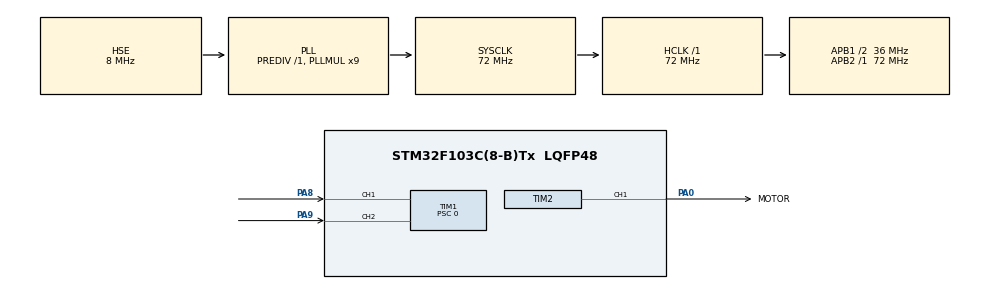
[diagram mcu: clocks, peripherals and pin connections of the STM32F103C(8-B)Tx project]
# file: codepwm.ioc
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Mcu.Family=STM32F1
Mcu.Name=STM32F103C(8-B)Tx
Mcu.Package=LQFP48
NVIC.PriorityGroup=NVIC_PRIORITYGROUP_4
NVIC.TIM3_IRQn=true\:0\:0\:false\:false\:true\:true\:true
PA0-WKUP.GPIO_Label=MOTOR
PA0-WKUP.Signal=S_TIM2_CH1_ETR
PA13.Mode=Serial_Wire
PA13.Signal=SYS_JTMS-SWDIO
PA14.Mode=Serial_Wire
PA14.Signal=SYS_JTCK-SWCLK
PA8.Signal=S_TIM1_CH1
PA9.Signal=S_TIM1_CH2
PD0-OSC_IN.Mode=HSE-External-Oscillator
PD0-OSC_IN.Signal=RCC_OSC_IN
PD1-OSC_OUT.Mode=HSE-External-Oscillator
PD1-OSC_OUT.Signal=RCC_OSC_OUT
ProjectManager.HeapSize=0x200
ProjectManager.StackSize=0x400
ProjectManager.TargetToolchain=MDK-ARM V5.32
RCC.AHBFreq_Value=72000000
RCC.APB1CLKDivider=RCC_HCLK_DIV2
RCC.APB1Freq_Value=36000000
RCC.APB1TimFreq_Value=72000000
RCC.APB2Freq_Value=72000000
RCC.APB2TimFreq_Value=72000000
RCC.HCLKFreq_Value=72000000
RCC.PLLMUL=RCC_PLL_MUL9
RCC.PLLSourceVirtual=RCC_PLLSOURCE_HSE
RCC.SYSCLKFreq_VALUE=72000000
RCC.SYSCLKSource=RCC_SYSCLKSOURCE_PLLCLK
RCC.USBFreq_Value=72000000
SH.S_TIM1_CH1.0=TIM1_CH1,Encoder_Interface
SH.S_TIM1_CH2.0=TIM1_CH2,Encoder_Interface
SH.S_TIM2_CH1_ETR.0=TIM2_CH1,PWM Generation1 CH1
TIM1.EncoderMode=TIM_ENCODERMODE_TI12
TIM1.Period=1560-1
TIM1.Prescaler=0
TIM2.Channel-PWM\ Generation1\ CH1=TIM_CHANNEL_1
TIM2.Period=100-1
TIM2.Prescaler=71
TIM3.Period=65535
TIM3.Prescaler=72-1
VP_TIM3_VS_ClockSourceINT.Mode=Internal
board=custom

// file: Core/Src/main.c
/* USER CODE BEGIN Header */
/**
  ******************************************************************************
  * @file           : main.c
  * @brief          : Main program body
  ******************************************************************************
  * @attention
  *
  * <h2><center>&copy; Copyright (c) 2026 STMicroelectronics.
  * All rights reserved.</center></h2>
  *
  * This software component is licensed by ST under BSD 3-Clause license,
  * the "License"; You may not use this file except in compliance with the
  * License. You may obtain a copy of the License at:
  *                        opensource.org/licenses/BSD-3-Clause
  *
  ******************************************************************************
  */
/* USER CODE END Header */
#include "main.h"

/* USER CODE BEGIN Includes */
#include <stdint.h>
/* USER CODE END Includes */

/* USER CODE BEGIN PTD */
typedef struct
{
    float Kp;
    float Ki;
    float Kd;

    float Integral;
    float Last_Error;
} PID_TypeDef;
/**
 * @brief 位置�? PID 计算函数
 * @param pid: 结构体指�?
 * @param target: 目标�? (比如目标温度 40�?)
 * @param measure: 当前测量�? (比如当前温度 30�?)
 * @return: 计算出的控制�? (比如 PWM 占空�?)
 */

/* USER CODE END PTD */

TIM_HandleTypeDef htim1;
TIM_HandleTypeDef htim2;
TIM_HandleTypeDef htim3;

/* USER CODE BEGIN PV */

volatile float rpm = 0.0f;
volatile float target_rpm = 100.0f;

PID_TypeDef speed_pid;
/* USER CODE END PV */

void SystemClock_Config(void);
static void MX_GPIO_Init(void);
static void MX_TIM2_Init(void);
static void MX_TIM1_Init(void);
static void MX_TIM3_Init(void);

/* USER CODE BEGIN 0 */
#define PID_DT                0.05f
#define PWM_MAX               100.0f
#define PWM_START_MIN          30.0f
#define RPM_STARTED_THRESHOLD   5.0f
#define ENCODER_CPR          1560.0f

float PID_Calculate(PID_TypeDef *pid,
                    float target,
                    float actual)
{
    float error;
    float derivative;
    float integral_candidate;
    float output;

    /* 1. 计算当前误差 */
    error = target - actual;

    /* 2. 微分：计算误差变化�?�度 */
    derivative = (error - pid->Last_Error) / PID_DT;

    /*
     * 3. 仅在未饱和或积分能使输出�?出饱和时更新积分�?
     * 避免高目标转速时积分持续堆积，随后出现冲高和断续停转�?
     */
    integral_candidate = pid->Integral + pid->Ki * error * PID_DT;
    output = pid->Kp * error
           + integral_candidate
           + pid->Kd * derivative;

    if (((output >= 0.0f) && (output <= PWM_MAX))
        || ((output > PWM_MAX) && (error < 0.0f))
        || ((output < 0.0f) && (error > 0.0f)))
    {
        pid->Integral = integral_candidate;
    }

    if (pid->Integral > PWM_MAX)
    {
        pid->Integral = PWM_MAX;
    }
    else if (pid->Integral < 0.0f)
    {
        pid->Integral = 0.0f;
    }

    /* 4. 使用�?终积分�?�计�? PID 输出 */
    output = pid->Kp * error
           + pid->Integral
           + pid->Kd * derivative;

    /* 保存本次误差，下�?次计算微分时使用 */
    pid->Last_Error = error;

    /* 5. PWM 限幅 */
    if (output > PWM_MAX)
    {
        output = PWM_MAX;
    }

    if (output < 0.0f)
    {
        output = 0.0f;
    }

    return output;
}
/* USER CODE END 0 */

int main(void)
{

  /* MCU Configuration--------------------------------------------------------*/

  /* Reset of all peripherals, Initializes the Flash interface and the Systick. */
  HAL_Init();

  /* Configure the system clock */
  SystemClock_Config();

  /* Initialize all configured peripherals */
  MX_GPIO_Init();
  MX_TIM2_Init();
  MX_TIM1_Init();
  MX_TIM3_Init();
  /* USER CODE BEGIN 2 */

HAL_TIM_PWM_Start(&htim2, TIM_CHANNEL_1);
__HAL_TIM_SET_COMPARE(&htim2, TIM_CHANNEL_1, 0);
/* PID 初始参数 */
speed_pid.Kp = 0.5f;
speed_pid.Ki = 0.20f;
speed_pid.Kd = 0.00f;

speed_pid.Integral = 0.0f;
speed_pid.Last_Error = 0.0f;

/* 启动编码�? */
HAL_TIM_Encoder_Start(&htim1, TIM_CHANNEL_ALL);
__HAL_TIM_SET_COUNTER(&htim1, 0);

/* �?有控制变量初始化后，再启�? 50 ms 控制周期 */
HAL_TIM_Base_Start_IT(&htim3);
  /* USER CODE END 2 */

  /* Infinite loop */
  /* USER CODE BEGIN WHILE */
  while (1)
  {

//	  if (count >60000)
//    {
//      count = 0;
//      __HAL_TIM_SET_COUNTER(&htim1, 0);
//    }
//    else if (count > 20)
//    {
//      count = 20;
//      __HAL_TIM_SET_COUNTER(&htim1, 20);
//    }
//
//__HAL_TIM_SET_COMPARE(&htim2, TIM_CHANNEL_1, count*5);

//
//  HAL_Delay(3000);

//  __HAL_TIM_SET_COMPARE(&htim2, TIM_CHANNEL_1, 0);
//  HAL_Delay(2000);

//  __HAL_TIM_SET_COMPARE(&htim2, TIM_CHANNEL_1, 50);
//  HAL_Delay(3000);
    /* USER CODE END WHILE */

  }
}

void SystemClock_Config(void)
{
  RCC_OscInitTypeDef RCC_OscInitStruct = {0};
  RCC_ClkInitTypeDef RCC_ClkInitStruct = {0};

  /** Initializes the RCC Oscillators according to the specified parameters
  * in the RCC_OscInitTypeDef structure.
  */
  RCC_OscInitStruct.OscillatorType = RCC_OSCILLATORTYPE_HSE;
  RCC_OscInitStruct.HSEState = RCC_HSE_ON;
  RCC_OscInitStruct.HSEPredivValue = RCC_HSE_PREDIV_DIV1;
  RCC_OscInitStruct.HSIState = RCC_HSI_ON;
  RCC_OscInitStruct.PLL.PLLState = RCC_PLL_ON;
  RCC_OscInitStruct.PLL.PLLSource = RCC_PLLSOURCE_HSE;
  RCC_OscInitStruct.PLL.PLLMUL = RCC_PLL_MUL9;
  if (HAL_RCC_OscConfig(&RCC_OscInitStruct) != HAL_OK)
  {
    Error_Handler();
  }
  /** Initializes the CPU, AHB and APB buses clocks
  */
  RCC_ClkInitStruct.ClockType = RCC_CLOCKTYPE_HCLK|RCC_CLOCKTYPE_SYSCLK
                              |RCC_CLOCKTYPE_PCLK1|RCC_CLOCKTYPE_PCLK2;
  RCC_ClkInitStruct.SYSCLKSource = RCC_SYSCLKSOURCE_PLLCLK;
  RCC_ClkInitStruct.AHBCLKDivider = RCC_SYSCLK_DIV1;
  RCC_ClkInitStruct.APB1CLKDivider = RCC_HCLK_DIV2;
  RCC_ClkInitStruct.APB2CLKDivider = RCC_HCLK_DIV1;

  if (HAL_RCC_ClockConfig(&RCC_ClkInitStruct, FLASH_LATENCY_2) != HAL_OK)
  {
    Error_Handler();
  }
}

static void MX_TIM1_Init(void)
{

  TIM_Encoder_InitTypeDef sConfig = {0};
  TIM_MasterConfigTypeDef sMasterConfig = {0};

  htim1.Instance = TIM1;
  htim1.Init.Prescaler = 0;
  htim1.Init.CounterMode = TIM_COUNTERMODE_UP;
  htim1.Init.Period = 1560-1;
  htim1.Init.ClockDivision = TIM_CLOCKDIVISION_DIV1;
  htim1.Init.RepetitionCounter = 0;
  htim1.Init.AutoReloadPreload = TIM_AUTORELOAD_PRELOAD_DISABLE;
  sConfig.EncoderMode = TIM_ENCODERMODE_TI12;
  sConfig.IC1Polarity = TIM_ICPOLARITY_RISING;
  sConfig.IC1Selection = TIM_ICSELECTION_DIRECTTI;
  sConfig.IC1Prescaler = TIM_ICPSC_DIV1;
  sConfig.IC1Filter = 0;
  sConfig.IC2Polarity = TIM_ICPOLARITY_RISING;
  sConfig.IC2Selection = TIM_ICSELECTION_DIRECTTI;
  sConfig.IC2Prescaler = TIM_ICPSC_DIV1;
  sConfig.IC2Filter = 0;
  if (HAL_TIM_Encoder_Init(&htim1, &sConfig) != HAL_OK)
  {
    Error_Handler();
  }
  sMasterConfig.MasterOutputTrigger = TIM_TRGO_RESET;
  sMasterConfig.MasterSlaveMode = TIM_MASTERSLAVEMODE_DISABLE;
  if (HAL_TIMEx_MasterConfigSynchronization(&htim1, &sMasterConfig) != HAL_OK)
  {
    Error_Handler();
  }

}

static void MX_TIM2_Init(void)
{

  TIM_MasterConfigTypeDef sMasterConfig = {0};
  TIM_OC_InitTypeDef sConfigOC = {0};

  htim2.Instance = TIM2;
  htim2.Init.Prescaler = 71;
  htim2.Init.CounterMode = TIM_COUNTERMODE_UP;
  htim2.Init.Period = 100-1;
  htim2.Init.ClockDivision = TIM_CLOCKDIVISION_DIV1;
  htim2.Init.AutoReloadPreload = TIM_AUTORELOAD_PRELOAD_DISABLE;
  if (HAL_TIM_PWM_Init(&htim2) != HAL_OK)
  {
    Error_Handler();
  }
  sMasterConfig.MasterOutputTrigger = TIM_TRGO_RESET;
  sMasterConfig.MasterSlaveMode = TIM_MASTERSLAVEMODE_DISABLE;
  if (HAL_TIMEx_MasterConfigSynchronization(&htim2, &sMasterConfig) != HAL_OK)
  {
    Error_Handler();
  }
  sConfigOC.OCMode = TIM_OCMODE_PWM1;
  sConfigOC.Pulse = 0;
  sConfigOC.OCPolarity = TIM_OCPOLARITY_HIGH;
  sConfigOC.OCFastMode = TIM_OCFAST_DISABLE;
  if (HAL_TIM_PWM_ConfigChannel(&htim2, &sConfigOC, TIM_CHANNEL_1) != HAL_OK)
  {
    Error_Handler();
  }
  HAL_TIM_MspPostInit(&htim2);

}

static void MX_TIM3_Init(void)
{

  TIM_ClockConfigTypeDef sClockSourceConfig = {0};
  TIM_MasterConfigTypeDef sMasterConfig = {0};

  htim3.Instance = TIM3;
  htim3.Init.Prescaler = 72-1;
  htim3.Init.CounterMode = TIM_COUNTERMODE_UP;
  htim3.Init.Period = 65535;
  htim3.Init.ClockDivision = TIM_CLOCKDIVISION_DIV1;
  htim3.Init.AutoReloadPreload = TIM_AUTORELOAD_PRELOAD_DISABLE;
  if (HAL_TIM_Base_Init(&htim3) != HAL_OK)
  {
    Error_Handler();
  }
  sClockSourceConfig.ClockSource = TIM_CLOCKSOURCE_INTERNAL;
  if (HAL_TIM_ConfigClockSource(&htim3, &sClockSourceConfig) != HAL_OK)
  {
    Error_Handler();
  }
  sMasterConfig.MasterOutputTrigger = TIM_TRGO_RESET;
  sMasterConfig.MasterSlaveMode = TIM_MASTERSLAVEMODE_DISABLE;
  if (HAL_TIMEx_MasterConfigSynchronization(&htim3, &sMasterConfig) != HAL_OK)
  {
    Error_Handler();
  }

}

static void MX_GPIO_Init(void)
{

  /* GPIO Ports Clock Enable */
  __HAL_RCC_GPIOD_CLK_ENABLE();
  __HAL_RCC_GPIOA_CLK_ENABLE();

}

/* USER CODE BEGIN 4 */
void HAL_TIM_PeriodElapsedCallback(TIM_HandleTypeDef *htim)
{
    int16_t encoder_count;
    float pwm;

    if (htim->Instance != TIM3)
    {
        return;
    }

    /* Count encoder edges during this 50 ms control period. */
    encoder_count = (int16_t)__HAL_TIM_GET_COUNTER(&htim1);
    __HAL_TIM_SET_COUNTER(&htim1, 0);

    rpm = (float)encoder_count * 60.0f
        / (ENCODER_CPR * PID_DT);

    /* 当前驱动只有正向 PWM，转速反馈使用大小，避免编码器相序反向�?? */
    if (rpm < 0.0f)
    {
        rpm = -rpm;
    }

    if (target_rpm <= 0.0f)
    {
        speed_pid.Integral = 0.0f;
        speed_pid.Last_Error = 0.0f;
        pwm = 0.0f;
    }
    else
    {
        pwm = PID_Calculate(&speed_pid, target_rpm, rpm);

        /* 启动时克服静摩擦；转动后允许低于启动占空比以稳定低转速�?? */
        if ((rpm < RPM_STARTED_THRESHOLD) && (pwm < PWM_START_MIN))
        {
            pwm = PWM_START_MIN;
        }
    }

    __HAL_TIM_SET_COMPARE(&htim2,
                          TIM_CHANNEL_1,
                          (uint32_t)(pwm + 0.5f));
}

/* USER CODE END 4 */

void Error_Handler(void)
{
  __disable_irq();
  while (1)
  {
  }
}

/************************ (C) COPYRIGHT STMicroelectronics *****END OF FILE****/
